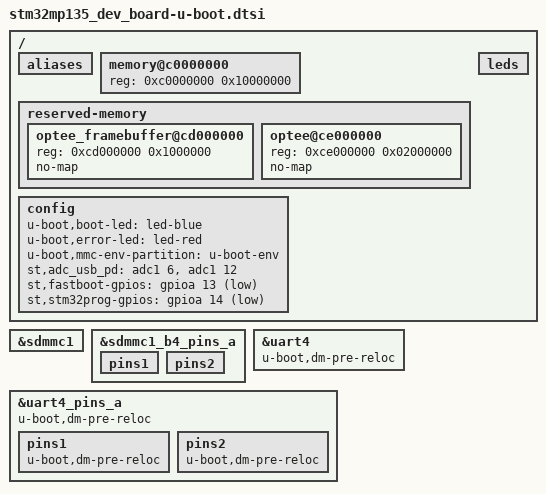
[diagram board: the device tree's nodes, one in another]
// SPDX-License-Identifier: (GPL-2.0-or-later OR BSD-3-Clause)
/*
 * Copyright (C) 2023, STMicroelectronics - All Rights Reserved
 * Author: STM32CubeMX code generation for STMicroelectronics.
 */

/* For more information on Device Tree configuration, please refer to
 * https://wiki.st.com/stm32mpu/wiki/Category:Device_tree_configuration
 */

/* USER CODE BEGIN includes */
#include "stm32mp13-u-boot.dtsi"
/* USER CODE END includes */

/ {

	/* USER CODE BEGIN root */

	aliases{
		
	};

	memory@c0000000 {
		device_type = "memory";
		reg = <0xc0000000 0x10000000>;
	};

	reserved-memory {
		#address-cells = <1>;
		#size-cells = <1>;
		ranges;

		optee_framebuffer@cd000000 {
				reg = <0xcd000000 0x1000000>;
				no-map;
		};

		optee@ce000000 {
				reg = <0xce000000 0x02000000>;
				no-map;
		};
	};


	config{
		u-boot,boot-led = "led-blue";
		u-boot,error-led = "led-red";
		u-boot,mmc-env-partition = "u-boot-env";
		st,adc_usb_pd = <&adc1 6>, <&adc1 12>;
		st,fastboot-gpios = <&gpioa 13 (GPIO_ACTIVE_LOW | GPIO_PULL_UP)>;
		st,stm32prog-gpios = <&gpioa 14 (GPIO_ACTIVE_LOW | GPIO_PULL_UP)>;
	};

	leds{
		
	};
	/* USER CODE END root */
}; /*root*/

&sdmmc1 {
	u-boot,dm-spl;
};

&sdmmc1_b4_pins_a {
	u-boot,dm-spl;
	pins1 {
		u-boot,dm-spl;
	};
	pins2 {
		u-boot,dm-spl;
	};
};

/* USER CODE BEGIN addons */
&uart4{
	u-boot,dm-pre-reloc;
};

&uart4_pins_a {
	u-boot,dm-pre-reloc;
	pins1 {
		u-boot,dm-pre-reloc;
	};
	pins2 {
		u-boot,dm-pre-reloc;
	};
};
/* USER CODE END addons */

